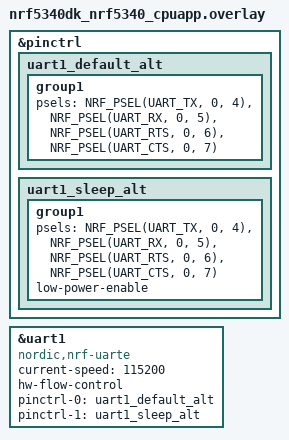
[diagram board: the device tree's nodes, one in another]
/* SPDX-License-Identifier: Apache-2.0 */

/*
 * Pins P0.4 and P0.5 must be connected to each other to loopback RX/TX.
 * Pins P0.6 and P0.7 must be connected to each other to loopback RTC/CTS.
 */

&pinctrl {
	uart1_default_alt: uart1_default_alt {
		group1 {
			psels = <NRF_PSEL(UART_TX, 0, 4)>,
				<NRF_PSEL(UART_RX, 0, 5)>,
				<NRF_PSEL(UART_RTS, 0, 6)>,
				<NRF_PSEL(UART_CTS, 0, 7)>;
		};
	};

	uart1_sleep_alt: uart1_sleep_alt {
		group1 {
			psels = <NRF_PSEL(UART_TX, 0, 4)>,
				<NRF_PSEL(UART_RX, 0, 5)>,
				<NRF_PSEL(UART_RTS, 0, 6)>,
				<NRF_PSEL(UART_CTS, 0, 7)>;
			low-power-enable;
		};
	};
};

dut: &uart1 {
	compatible = "nordic,nrf-uarte";
	current-speed = <115200>;
	hw-flow-control;
	status = "okay";
	pinctrl-0 = <&uart1_default_alt>;
	pinctrl-1 = <&uart1_sleep_alt>;
	pinctrl-names = "default", "sleep";
};
